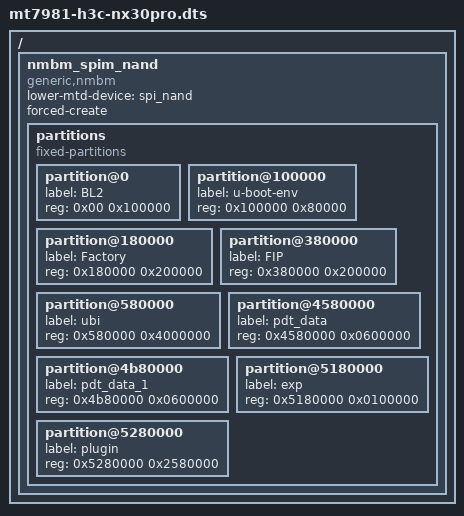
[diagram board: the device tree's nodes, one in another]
/dts-v1/;
#include "mt7981-h3c-nx30pro-base.dtsi"

/ {
	nmbm_spim_nand {
		compatible = "generic,nmbm";

		#address-cells = <1>;
		#size-cells = <1>;

		lower-mtd-device = <&spi_nand>;
		forced-create;

		partitions {
			compatible = "fixed-partitions";
			#address-cells = <1>;
			#size-cells = <1>;

			partition@0 {
				label = "BL2";
				reg = <0x00 0x100000>;
			};

			partition@100000 {
				label = "u-boot-env";
				reg = <0x100000 0x80000>;
			};

			partition@180000 {
				label = "Factory";
				reg = <0x180000 0x200000>;
			};

			partition@380000 {
				label = "FIP";
				reg = <0x380000 0x200000>;
			};

			partition@580000 {
				label = "ubi";
				reg = <0x580000 0x4000000>;
			};
			
			partition@4580000 {
				label = "pdt_data";
				reg = <0x4580000 0x0600000>;
			};

			partition@4b80000 {
				label = "pdt_data_1";
				reg = <0x4b80000 0x0600000>;
			};

			partition@5180000 {
				label = "exp";
				reg = <0x5180000 0x0100000>;
			};

			partition@5280000 {
				label = "plugin";
				reg = <0x5280000 0x2580000>;
			};

		};
	};
};
